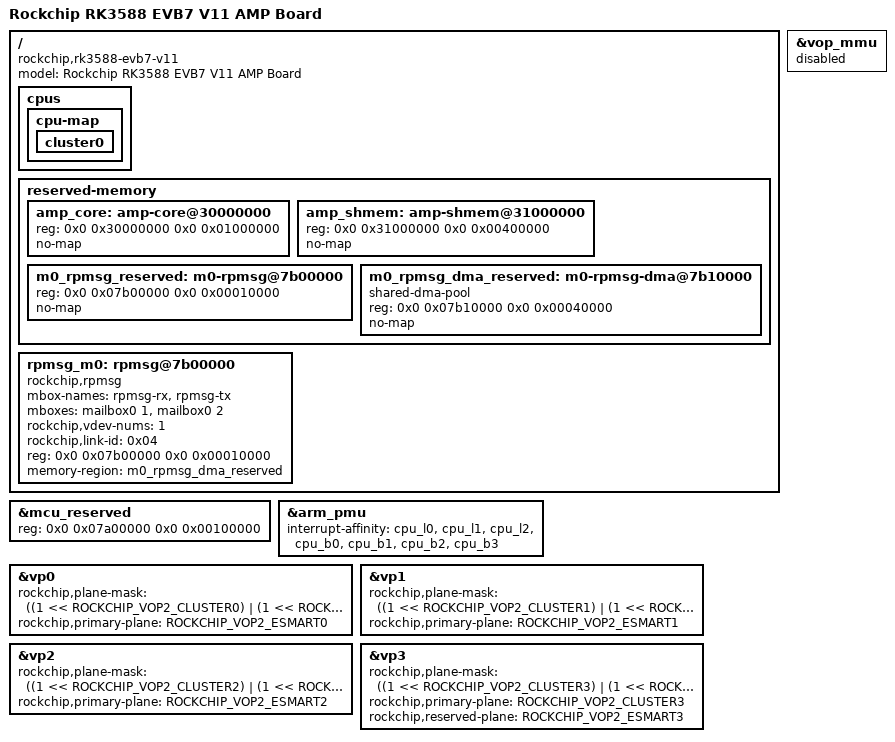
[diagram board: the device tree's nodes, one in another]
// SPDX-License-Identifier: (GPL-2.0+ OR MIT)
/*
 * RK3588 EVB7 V11 - AMP variant
 * Linux runs on 7 cores; cpu_l3 (MPIDR 0x300) is handed to an AMP firmware.
 * Ported from rk3588-evb1-lp4-v10-linux-amp.dts (AMP deltas only).
 */

/dts-v1/;

#include "rk3588-evb7-v11.dtsi"
#include "rk3588-evb7-v11-imx415.dtsi"
#include "rk3588-linux.dtsi"
#include "rk3588-amp.dtsi"

/ {
model = "Rockchip RK3588 EVB7 V11 AMP Board";
compatible = "rockchip,rk3588-evb7-v11", "rockchip,rk3588";

cpus {
cpu-map {
cluster0 {
/delete-node/ core3;
};
};
};

reserved-memory {
#address-cells = <2>;
#size-cells = <2>;
ranges;

/* Dedicated AMP core region: high, no-map, clear of kernel/M0/OP-TEE/CMA */
amp_core: amp-core@30000000 {
reg = <0x0 0x30000000 0x0 0x01000000>;
no-map;
};

/* rpmsg/shared-mem for remote core; relocated off 0x8200000 (overlapped OP-TEE) */
amp_shmem: amp-shmem@31000000 {
reg = <0x0 0x31000000 0x0 0x00400000>;
no-map;
};

/*
 * rpmsg link towards the PMU Cortex-M0, carved out of the second half of
 * mcu@7a00000 (shrunk to 1MB below) so no new memory has to be reserved.
 * The M0 reaches these same bytes through its off-chip DDR window, which
 * the AMP FIT aims at 0x07b00000 via exsram_start.
 *
 * Sizes follow include/linux/rpmsg/rockchip_rpmsg.h: the driver places
 * vring0 at the start of this region and vring1 one RPMSG_VRING_SIZE
 * (0x8000) later, so RPMSG_VRING_OVERHEAD = 0x10000 is the minimum.
 */
m0_rpmsg_reserved: m0-rpmsg@7b00000 {
reg = <0x0 0x07b00000 0x0 0x00010000>;
no-map;
};

m0_rpmsg_dma_reserved: m0-rpmsg-dma@7b10000 {
compatible = "shared-dma-pool";
reg = <0x0 0x07b10000 0x0 0x00040000>;
no-map;
};
};

/*
 * Second rpmsg instance, for the M0. rockchip_rpmsg_mbox is a plain platform
 * driver whose vring addresses come from each node's own reg, so a second
 * node probes as an independent link.
 *
 * It shares mailbox0 with the cpu_l3 link but uses the two free channels:
 * cpu_l3 holds ch0 (its rx) and ch3 (its tx), so this link takes ch1 and ch2.
 *
 * mailbox1 was tried first and does not work: its registers are inaccessible,
 * and rockchip_mbox_startup() died with a synchronous external abort during
 * probe, which killed kernel_init and with it the whole boot. Its probe-time
 * "version: 0x0100" message is not evidence to the contrary - for the 1.0.0
 * controller that is a driver constant, so probe never reads a register.
 *
 * The link-id packs a 4-bit master cpu id and a 4-bit remote id; the RK3576 AMP
 * dtsi documents the MCU as remote 4, so 0x04.
 */
rpmsg_m0: rpmsg@7b00000 {
compatible = "rockchip,rpmsg";
mbox-names = "rpmsg-rx", "rpmsg-tx";
mboxes = <&mailbox0 1 &mailbox0 2>;
rockchip,vdev-nums = <1>;
rockchip,link-id = <0x04>;
reg = <0x0 0x07b00000 0x0 0x00010000>;
memory-region = <&m0_rpmsg_dma_reserved>;
status = "okay";
};
};

/* Shrink the M0 carveout to 1MB: the upper half now holds the rpmsg vrings and
 * buffer pool declared above, and the M0 firmware caps its heap accordingly
 * (CONFIG_RAM_SIZE = 1MB) so it cannot grow into them.
 */
&mcu_reserved {
reg = <0x0 0x07a00000 0x0 0x00100000>;
};

/* mailbox1 deliberately left disabled: its registers are inaccessible on this
 * SoC and touching them aborts. Both rpmsg links run on mailbox0, which the
 * shared dtsi already enables.
 */

&arm_pmu {
interrupt-affinity = <&cpu_l0>, <&cpu_l1>, <&cpu_l2>,
<&cpu_b0>, <&cpu_b1>, <&cpu_b2>, <&cpu_b3>;
};

/*
 * Hand vp3's Esmart3 window to the AMP core.
 *
 * vp3 drives the MIPI-DSI panel and Linux keeps doing so: it owns the mode, the
 * clocks, the DSI PHY and the panel. What it gives up is one overlay window,
 * which the AMP core then points at its own framebuffer. The alternative -
 * taking the whole video port - would mean reimplementing all of that
 * initialisation on a core that has no display driver at all.
 *
 * Three properties, each doing something different:
 *
 * plane-mask has to be spelled out for every video port, not just vp3.
 * vop2_plane_mask_check() (rockchip_drm_vop2.c:16295) requires the union of all
 * four masks to equal the SoC's full window set - 0x3cf here - and on any
 * mismatch it prints "use default plane mask" and calls vop2_plane_mask_assign(),
 * which throws away primary-plane too. Leaving vp0..vp2 unset (mask 0) or
 * dropping Esmart3 from vp3 both fail that check, so the assignment below simply
 * restates the driver's own default distribution. Only primary-plane and
 * reserved-plane actually differ from stock.
 *
 * Keeping Esmart3 in the mask is not just a way to satisfy that check - almost
 * everything the other core needs falls out of it, because the driver derives
 * those things from win_mask rather than from how many windows Linux is
 * actually using:
 *
 *   - vop2_layer_map_initial() (rockchip_drm_vop2.c:4585) walks win_mask at
 *     probe and assigns hardware layers in order. vp0..vp2 take two windows
 *     each, so vp3 gets layers 6 and 7, and Esmart3 - the higher phys_id - lands
 *     on 7, the topmost. The same loop sets win_vp_id[Esmart3] = 3.
 *   - vop2_calc_bg_ovl_and_port_mux() (:12398) sizes each port's slice of the
 *     mixer chain from hweight32(win_mask), and the last video port is hardcoded
 *     to take everything remaining (:12437). So layer 7 is in vp3's blend chain.
 *   - vop2_setup_alpha()'s tail loop (:11985) runs to hweight32(win_mask) and
 *     configures the mixer for layer 7 even though Linux has no plane there. For
 *     a source with no alpha channel the values it writes are the same ones it
 *     would write for a real XRGB8888 plane: an opaque overwrite.
 *
 * primary-plane moves to Cluster3 because Esmart3 was it, and a CRTC without a
 * primary plane cannot be given a framebuffer, which means no modeset and no
 * timing on the panel at all.
 *
 * reserved-plane does exactly one thing on this SoC, and it is the one thing
 * that matters: it switches Linux's commits on vp3 from the per-port cfg_done
 * register to the per-window one (rockchip_drm_vop2.c:1961), and the bitmask
 * written there only ever contains windows Linux itself touched in that commit
 * (:2307). Register writes made from the other core therefore sit in the VOP's
 * shadow copy until that core commits them, instead of being latched by whatever
 * frame Linux happens to be pushing.
 *
 * It does not also do the layer routing that the same property does on RK3576:
 * that code (:12580) is inside vop3_setup_layer_sel_for_vp(), and is_vop3()
 * returns false for RK3588 (:1260), so RK3588 goes through
 * vop2_setup_layer_mixer_for_vp() (:13259), which has no notion of a reserved
 * plane. Hence the win_mask reasoning above.
 *
 * Two consequences of Esmart3 staying in the mask, both accepted:
 * vop2_disable_all_planes_for_crtc() walks win_mask and does not skip reserved
 * planes, so a modeset or CRTC shutdown (call sites 5996/9078/10630/13949) will
 * switch the window off - the other core reprograms it every frame, so that
 * costs one frame rather than the display. And Linux still registers a DRM plane
 * for Esmart3, so nothing but discipline stops a client from binding it; there
 * is no compositor on this target.
 *
 * The window's power domain is not a worry on this SoC: the driver turns PD_ESMART
 * on at init and refuses to control it dynamically
 * (rockchip_drm_vop2.c:4781 and vop2_ignore_dynamic_control_sub_pd()).
 */

&vp0 {
	rockchip,plane-mask = <((1 << ROCKCHIP_VOP2_CLUSTER0) | (1 << ROCKCHIP_VOP2_ESMART0))>;
	rockchip,primary-plane = <ROCKCHIP_VOP2_ESMART0>;
};

&vp1 {
	rockchip,plane-mask = <((1 << ROCKCHIP_VOP2_CLUSTER1) | (1 << ROCKCHIP_VOP2_ESMART1))>;
	rockchip,primary-plane = <ROCKCHIP_VOP2_ESMART1>;
};

&vp2 {
	rockchip,plane-mask = <((1 << ROCKCHIP_VOP2_CLUSTER2) | (1 << ROCKCHIP_VOP2_ESMART2))>;
	rockchip,primary-plane = <ROCKCHIP_VOP2_ESMART2>;
};

&vp3 {
	rockchip,plane-mask = <((1 << ROCKCHIP_VOP2_CLUSTER3) | (1 << ROCKCHIP_VOP2_ESMART3))>;
	rockchip,primary-plane = <ROCKCHIP_VOP2_CLUSTER3>;
	rockchip,reserved-plane = <ROCKCHIP_VOP2_ESMART3>;
};

/*
 * The VOP's IOMMU has to go, because a plane driven from another core can only be
 * given a physical address. With no IOMMU the DRM side does not merely tolerate
 * that - it switches to it: rockchip_gem_create_object() forces contiguous
 * allocation and programs dma_handle rather than an IOVA when private->domain is
 * NULL (rockchip_drm_gem.c:455). Both sides then speak physical addresses.
 *
 * Evidence that this is needed rather than assumed: with the IOMMU on, the plane's
 * address reads back as 0x0 in /sys/kernel/debug/dri/0/summary, which cannot be a
 * physical address on this board - the first IOVA handed out is zero.
 *
 * Cost: every DRM buffer becomes CMA. There is a 256MB CMA pool and no compositor
 * running here, and video decode has its own IOMMU, so nothing else is affected.
 */

&vop_mmu {
	status = "disabled";
};

/* Drop the stock amp-shmem@8200000 (overlaps OP-TEE @0x08400000); replaced above */
/delete-node/ &amp_shmem_reserved;

/* cpu_l3 is owned by the AMP firmware; remove from Linux */
/delete-node/ &cpu_l3;
